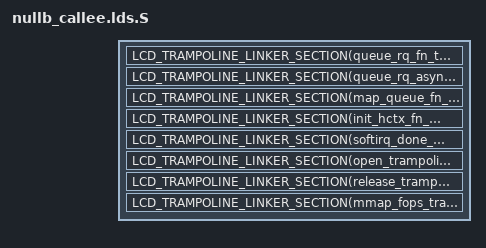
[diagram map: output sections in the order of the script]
#include <liblcd/trampoline_link.h>

SECTIONS
{
	LCD_TRAMPOLINE_LINKER_SECTION(queue_rq_fn_trampoline)
	LCD_TRAMPOLINE_LINKER_SECTION(queue_rq_async_fn_trampoline)
	LCD_TRAMPOLINE_LINKER_SECTION(map_queue_fn_trampoline)
	LCD_TRAMPOLINE_LINKER_SECTION(init_hctx_fn_trampoline)
	LCD_TRAMPOLINE_LINKER_SECTION(softirq_done_fn_trampoline)
	LCD_TRAMPOLINE_LINKER_SECTION(open_trampoline)
	LCD_TRAMPOLINE_LINKER_SECTION(release_trampoline)
	LCD_TRAMPOLINE_LINKER_SECTION(mmap_fops_trampoline)
}
INSERT AFTER .text;
